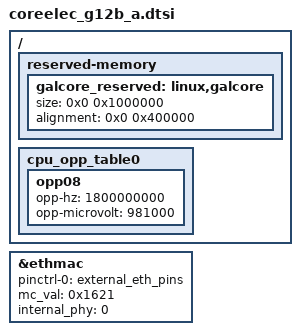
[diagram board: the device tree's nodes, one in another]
#include "g12b_a311d_w400_a.dts"
#include "coreelec_g12_common.dtsi"

/{
	reserved-memory {
		galcore_reserved:linux,galcore {
			size = <0x0 0x1000000>;
			alignment = <0x0 0x400000>;
		};
	};

	cpu_opp_table0: cpu_opp_table0 {
		opp08 {
			opp-hz = /bits/ 64 <1800000000>;
			opp-microvolt = <981000>;
		};
	};
};

&ethmac {
	pinctrl-names = "external_eth_pins";
	pinctrl-0 = <&external_eth_pins>;
	mc_val = <0x1621>;
	internal_phy=<0>;
};
